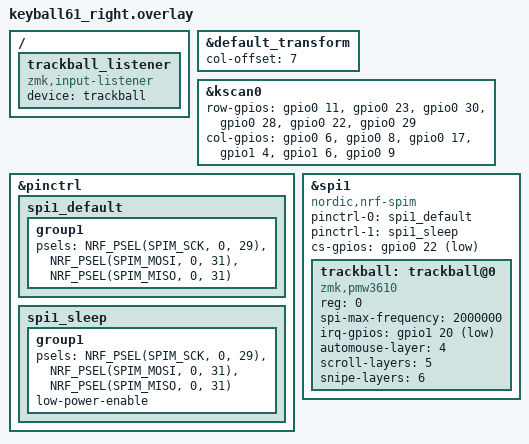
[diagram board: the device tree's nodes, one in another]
/*
 * Copyright (c) 2020 ZMK Contributors
 *
 * SPDX-License-Identifier: MIT
 */
 
#include "keyball61.dtsi"

&default_transform {
    col-offset = <7>;
};

&kscan0 {
	row-gpios
            = <&gpio0 11 (GPIO_ACTIVE_HIGH | GPIO_PULL_DOWN)>
            , <&gpio0 23 (GPIO_ACTIVE_HIGH | GPIO_PULL_DOWN)>
            , <&gpio0 30  (GPIO_ACTIVE_HIGH | GPIO_PULL_DOWN)>
            , <&gpio0 28 (GPIO_ACTIVE_HIGH | GPIO_PULL_DOWN)>
            , <&gpio0 22 (GPIO_ACTIVE_HIGH | GPIO_PULL_DOWN)>
            , <&gpio0 29 (GPIO_ACTIVE_HIGH | GPIO_PULL_DOWN)>
        ;
	col-gpios
            =  <&gpio0 6  GPIO_ACTIVE_HIGH>
            ,  <&gpio0 8  GPIO_ACTIVE_HIGH>
            , <&gpio0 17  GPIO_ACTIVE_HIGH>
            , <&gpio1 4  GPIO_ACTIVE_HIGH>
            , <&gpio1 6  GPIO_ACTIVE_HIGH>
            , <&gpio0 9  GPIO_ACTIVE_HIGH>
		;
	};

&pinctrl {
    spi1_default: spi1_default {
        group1 {
            psels = <NRF_PSEL(SPIM_SCK, 0, 29)>,
                <NRF_PSEL(SPIM_MOSI, 0, 31)>,
                <NRF_PSEL(SPIM_MISO, 0, 31)>;
        };
    };

    spi1_sleep: spi1_sleep {
        group1 {
            psels = <NRF_PSEL(SPIM_SCK, 0, 29)>,
                <NRF_PSEL(SPIM_MOSI, 0, 31)>,
                <NRF_PSEL(SPIM_MISO, 0, 31)>;
            low-power-enable;
        };
    };
};

&spi1 {
    status = "okay";
    compatible = "nordic,nrf-spim";
    pinctrl-0 = <&spi1_default>;
    pinctrl-1 = <&spi1_sleep>;
    pinctrl-names = "default", "sleep";
    cs-gpios = <&gpio0 22 GPIO_ACTIVE_LOW>;

    trackball: trackball@0 {
        status = "okay";
        compatible = "zmk,pmw3610";
        reg = <0>;
        spi-max-frequency = <2000000>;
        irq-gpios = <&gpio1 20 (GPIO_ACTIVE_LOW | GPIO_PULL_UP)>;
        automouse-layer = <4>;
	scroll-layers = <5>;
	snipe-layers = <6>;
    };
};


/ {
  trackball_listener {
    compatible = "zmk,input-listener";
    device = <&trackball>;

  };
};
